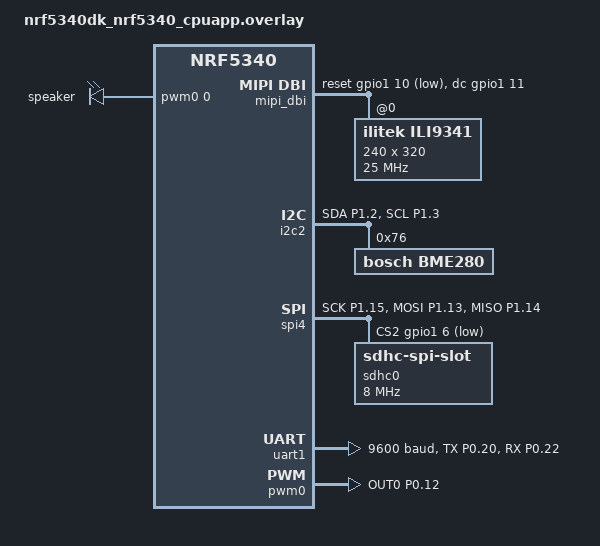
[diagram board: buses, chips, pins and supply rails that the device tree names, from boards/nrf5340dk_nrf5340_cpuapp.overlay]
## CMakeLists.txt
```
#
# Copyright (c) 2024 Nordic Semiconductor
#
# SPDX-License-Identifier: LicenseRef-Nordic-5-Clause
#

cmake_minimum_required(VERSION 3.20.0)
find_package(Zephyr REQUIRED HINTS $ENV{ZEPHYR_BASE})
project(INDOOR)

# Add SRAMLink library
add_subdirectory(lib/sramlink)

target_sources(app PRIVATE src/main.c src/font.c src/font_16x16.c src/prayerTime.c src/world_cities.c src/sd_card.c)

# Conditional display driver - SPI TFT for nrf5340dk and nrf52840dk, parallel for nrf52dk
if(BOARD MATCHES "nrf5340" OR BOARD MATCHES "nrf52840")
    target_sources(app PRIVATE src/ili9341_tft.c)
    message(STATUS "Using ili9341_tft.c (SPI TFT with HMI) for ${BOARD}")
else()
    target_sources(app PRIVATE src/ili9341_parallel.c)
    message(STATUS "Using ili9341_parallel.c (parallel interface) for ${BOARD}")
endif()

# Conditional GPS module selection (default to NEO-7M)
# To use NEO-6M: add -DUSE_NEO6M_GPS=1 to build command
# To use NEO-7M: add -DUSE_NEO7M_GPS=1 to build command (or use default)
if(DEFINED USE_NEO6M_GPS)
    target_sources(app PRIVATE src/gps_neo6m.c)
    target_compile_definitions(app PRIVATE USE_NEO6M_GPS)
    message(STATUS "Using NEO-6M GPS module")
elseif(DEFINED USE_NEO7M_GPS)
    target_sources(app PRIVATE src/gps_neo7m.c)
    target_compile_definitions(app PRIVATE USE_NEO7M_GPS)
    message(STATUS "Using NEO-7M GPS module")
else()
    # Default to NEO-7M
    target_sources(app PRIVATE src/gps_neo7m.c)
    target_compile_definitions(app PRIVATE USE_NEO7M_GPS)
    message(STATUS "Using NEO-7M GPS module (default)")
endif()

# Conditional speaker support - include speaker.c (will compile conditionally based on PWM availability)
if(CONFIG_PWM)
    target_sources(app PRIVATE src/speaker.c)
    message(STATUS "Speaker support enabled (PWM available)")
else()
    message(STATUS "Speaker support disabled (no PWM)")
endif()

# BME280 sensor support - include bme280_sensor.c if sensor is enabled
if(CONFIG_BME280)
    target_sources(app PRIVATE src/bme280_sensor.c)
    message(STATUS "BME280 sensor support enabled")
else()
    message(STATUS "BME280 sensor support disabled")
endif()

# PmodALS ambient light sensor support - only for nRF5340 (uses SPI4)
if(BOARD MATCHES "nrf5340")
    target_sources(app PRIVATE src/pmodals_sensor.c)
    message(STATUS "PmodALS ambient light sensor support enabled")
else()
    message(STATUS "PmodALS ambient light sensor disabled (not supported on ${BOARD})")
endif()

# FT6206 touch screen support - only for nRF5340 (uses I2C0)
if(BOARD MATCHES "nrf5340")
    target_sources(app PRIVATE src/ft6206_touch.c)
    target_compile_definitions(app PRIVATE CONFIG_FT6206_TOUCH)
    message(STATUS "FT6206 touch screen support enabled (I2C0)")
else()
    message(STATUS "FT6206 touch screen disabled (not supported on ${BOARD})")
endif()

# SRAMLink protocol support
if(CONFIG_SRAMLINK)
    target_sources(app PRIVATE src/sramlink/sramlink_app.c)
    target_include_directories(app PRIVATE
        ${CMAKE_CURRENT_SOURCE_DIR}/lib/sramlink
        ${CMAKE_CURRENT_SOURCE_DIR}/lib/sramlink/core
        ${CMAKE_CURRENT_SOURCE_DIR}/lib/sramlink/drivers
        ${CMAKE_CURRENT_SOURCE_DIR}/lib/sramlink/messages
        ${CMAKE_CURRENT_SOURCE_DIR}/lib/sramlink/util
    )
    target_link_libraries(app PRIVATE sramlink)
    message(STATUS "SRAMLink protocol support enabled")
endif()
```

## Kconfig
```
#
# INDOOR Project Kconfig
#

# Source Zephyr Kconfig
source "Kconfig.zephyr"

# Source SRAMLink library Kconfig
rsource "lib/sramlink/Kconfig"
```

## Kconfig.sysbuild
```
source "${ZEPHYR_BASE}/share/sysbuild/Kconfig"

config NRF_DEFAULT_IPC_RADIO
    default y

config NETCORE_IPC_RADIO_BT_HCI_IPC
    default y
```

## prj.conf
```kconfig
CONFIG_GPIO=y
CONFIG_SPI=y
CONFIG_DISPLAY=y
CONFIG_DISPLAY_INIT_PRIORITY=90
CONFIG_ILI9341=y
CONFIG_SERIAL=y
CONFIG_UART_INTERRUPT_DRIVEN=y
CONFIG_UART_ASYNC_API=y
CONFIG_PRINTK=y
CONFIG_PWM=y

# Console configuration - Using RTT instead of UART
CONFIG_CONSOLE=y
CONFIG_UART_CONSOLE=n
CONFIG_RTT_CONSOLE=y
CONFIG_USE_SEGGER_RTT=y
CONFIG_LOG_BACKEND_RTT=y

CONFIG_I2C=y

# Use NFC pins (P0.02, P0.03) as GPIOs for FT6206 touch I2C0
CONFIG_NFCT_PINS_AS_GPIOS=y

# BME280 sensor configuration
CONFIG_SENSOR=y
CONFIG_BME280=y

# PmodALS ambient light sensor configuration
# Uses SPI interface (shared with display on SPI4)
# Note: PmodALS driver is custom implementation, not using Zephyr sensor API

# Logging and support configs
CONFIG_LOG=y
CONFIG_CBPRINTF_FP_SUPPORT=y
CONFIG_RESET_ON_FATAL_ERROR=n

# Heap memory management
CONFIG_HEAP_MEM_POOL_SIZE=32768

# Stack size configuration
CONFIG_MAIN_STACK_SIZE=4096
CONFIG_SYSTEM_WORKQUEUE_STACK_SIZE=2048

# Events (for athan thread signaling)
CONFIG_EVENTS=y

# SD Card and File System Support
CONFIG_FILE_SYSTEM=y
CONFIG_FAT_FILESYSTEM_ELM=y
CONFIG_FS_FATFS_LFN=y
CONFIG_FS_FATFS_MAX_LFN=255

# SD Card / Disk Access
CONFIG_DISK_ACCESS=y
CONFIG_DISK_DRIVER_SDMMC=y
CONFIG_SDMMC_STACK=y
CONFIG_MMC_STACK=y

# SD Card Tuning
CONFIG_SD_INIT_TIMEOUT=5000
CONFIG_SD_RETRY_COUNT=30
CONFIG_SD_OCR_RETRY_COUNT=3000
CONFIG_SD_CMD_TIMEOUT=1000
CONFIG_SD_CMD_RETRIES=10
CONFIG_SD_DATA_RETRIES=10

# SD Card Debug Logging (optional - can be disabled later)
CONFIG_SD_LOG_LEVEL_INF=y
CONFIG_SDHC_LOG_LEVEL_INF=y

# ============================================================
# SRAMLink Protocol Support (optional)
# Uncomment the following to enable SRAMLink wireless protocol
# Or use: west build -- -DOVERLAY_CONFIG=prj_sramlink.conf
# ============================================================
# CONFIG_IEEE802154=y
# CONFIG_IEEE802154_NRF5=y
# CONFIG_SRAMLINK=y
# CONFIG_SRAMLINK_RADIO_CHANNEL=15
# CONFIG_NVS=y
# CONFIG_FLASH=y
# CONFIG_FLASH_MAP=y
# CONFIG_MBEDTLS=y
# CONFIG_MBEDTLS_BUILTIN=y
# CONFIG_MBEDTLS_CIPHER_AES_ENABLED=y
```

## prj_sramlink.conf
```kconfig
#
# SRAMLink Protocol Configuration Overlay
#
# Use this with: west build -b <board> -- -DOVERLAY_CONFIG=prj_sramlink.conf
#

# nRF 802.15.4 Radio Driver (standalone, no networking stack)
CONFIG_NRF_802154_RADIO_DRIVER=y
CONFIG_NRF_802154_SL_OPENSOURCE=y
CONFIG_MPSL=n

# SRAMLink Protocol
CONFIG_SRAMLINK=y
CONFIG_SRAMLINK_LOG_LEVEL=3
CONFIG_SRAMLINK_RADIO_CHANNEL=15
CONFIG_SRAMLINK_TX_POWER=4

# Crypto support (for message encryption) - using Nordic Security
CONFIG_ENTROPY_GENERATOR=y
CONFIG_NRF_SECURITY=y
CONFIG_MBEDTLS=y
CONFIG_MBEDTLS_ENABLE_HEAP=y
CONFIG_MBEDTLS_HEAP_SIZE=8192
CONFIG_PSA_WANT_ALG_CBC_NO_PADDING=y
CONFIG_PSA_WANT_ALG_ECB_NO_PADDING=y
CONFIG_PSA_WANT_KEY_TYPE_AES=y

# Enable legacy mbedTLS AES API
CONFIG_MBEDTLS_AES_C=y
CONFIG_MBEDTLS_CIPHER_AES_ENABLED=y
CONFIG_MBEDTLS_LEGACY_CRYPTO_C=y

# NVS for pairing persistence
CONFIG_NVS=y
CONFIG_FLASH=y
CONFIG_FLASH_PAGE_LAYOUT=y
CONFIG_FLASH_MAP=y
CONFIG_MPU_ALLOW_FLASH_WRITE=y

# Increase stack size for crypto operations
CONFIG_MAIN_STACK_SIZE=8192
```

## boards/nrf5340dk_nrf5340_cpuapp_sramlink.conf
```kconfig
#
# SRAMLink Configuration for nRF5340-DK (App Core)
#
# Uses serialized 802.15.4 driver - network core runs ipc_radio
#

# Enable UART console (override RTT from main prj.conf)
CONFIG_UART_CONSOLE=y
CONFIG_RTT_CONSOLE=n
CONFIG_LOG_BACKEND_RTT=n
CONFIG_LOG_BACKEND_UART=y

# SRAMLink Protocol
CONFIG_SRAMLINK=y
CONFIG_SRAMLINK_LOG_LEVEL=3
CONFIG_SRAMLINK_RADIO_CHANNEL=15
CONFIG_SRAMLINK_TX_POWER=4

# Serialized 802.15.4 driver (communicates with network core)
CONFIG_NRF_802154_SER_HOST=y

# Crypto support
CONFIG_ENTROPY_GENERATOR=y
CONFIG_NRF_SECURITY=y
CONFIG_MBEDTLS=y
CONFIG_MBEDTLS_ENABLE_HEAP=y
CONFIG_MBEDTLS_HEAP_SIZE=8192
CONFIG_PSA_WANT_ALG_CBC_NO_PADDING=y
CONFIG_PSA_WANT_ALG_ECB_NO_PADDING=y
CONFIG_PSA_WANT_KEY_TYPE_AES=y
CONFIG_MBEDTLS_AES_C=y
CONFIG_MBEDTLS_CIPHER_AES_ENABLED=y
CONFIG_MBEDTLS_LEGACY_CRYPTO_C=y

# NVS for pairing persistence
CONFIG_NVS=y
CONFIG_FLASH=y
CONFIG_FLASH_PAGE_LAYOUT=y
CONFIG_FLASH_MAP=y
CONFIG_MPU_ALLOW_FLASH_WRITE=y

# Increase stack size
CONFIG_MAIN_STACK_SIZE=8192
```

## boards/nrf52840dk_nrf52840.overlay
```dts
// nRF52840 DK to Adafruit 1947 LCD Overlay with GPS
&i2c0 {
    status = "okay";
    pinctrl-0 = <&i2c0_default>;
    pinctrl-1 = <&i2c0_sleep>;
    pinctrl-names = "default", "sleep";

    bme280: bme280@76 {
        compatible = "bosch,bme280";
        reg = <0x76>;
        label = "BME280";
    };
};

&spi0 { status = "disabled"; };
&i2c1 { status = "disabled"; };

&spi1 {
    status = "okay";
    pinctrl-0 = <&spi1_default>;
    pinctrl-1 = <&spi1_sleep>;
    pinctrl-names = "default", "sleep";
    cs-gpios = <&gpio1 12 GPIO_ACTIVE_LOW>,  // P1.12 as TFT CS
               <&gpio1 7 GPIO_ACTIVE_LOW>;   // P1.07 as ALS CS
};

/* Add pinctrl node for spi1 */
&pinctrl {
    i2c0_default: i2c0_default {
        group1 {
            psels = <NRF_PSEL(TWIM_SCL, 0, 28)>,
                    <NRF_PSEL(TWIM_SDA, 0, 29)>;
        };
    };

    i2c0_sleep: i2c0_sleep {
        group1 {
            psels = <NRF_PSEL(TWIM_SCL, 0, 28)>,
                    <NRF_PSEL(TWIM_SDA, 0, 29)>;
            low-power-enable;
        };
    };

    spi1_default: spi1_default {
        group1 {
            psels = <NRF_PSEL(SPIM_SCK, 1, 15)>,   // P1.15 SCLK
                    <NRF_PSEL(SPIM_MOSI, 1, 13)>,  // P1.13 MOSI
                    <NRF_PSEL(SPIM_MISO, 1, 14)>;  // P1.14 MISO
         };
    };

    spi1_sleep: spi1_sleep {
        group1 {
            psels = <NRF_PSEL(SPIM_SCK, 1, 15)>,
                    <NRF_PSEL(SPIM_MOSI, 1, 13)>,
                    <NRF_PSEL(SPIM_MISO, 1, 14)>;
            low-power-enable;
        };
    };

    pwm0_default: pwm0_default {
        group1 {
            psels = <NRF_PSEL(PWM_OUT0, 0, 12)>;  // P0.12 Speaker PWM
        };
    };

    pwm0_sleep: pwm0_sleep {
        group1 {
            psels = <NRF_PSEL(PWM_OUT0, 0, 12)>;
            low-power-enable;
        };
    };
};

/ {
    aliases {
        gps-uart = &uart1;
    };

    chosen {
        zephyr,console = &uart0;
        zephyr,shell-uart = &uart0;
        zephyr,uart-mcumgr = &uart0;
        zephyr,display = &ili9341;
    };

    backlight: backlight {
        compatible = "gpio-leds";
        backlight_gpio: backlight_gpio {
            gpios = <&gpio0 3 GPIO_ACTIVE_LOW>;
            label = "Display Backlight";
        };
    };

    pwmleds {
        compatible = "pwm-leds";
        speaker: speaker_pwm_led {
            pwms = <&pwm0 0 PWM_HZ(1000) PWM_POLARITY_NORMAL>;
        };
    };

    mipi_dbi {
        compatible = "zephyr,mipi-dbi-spi";
        spi-dev = <&spi1>;
        dc-gpios = <&gpio1 11 GPIO_ACTIVE_HIGH>;
        status = "okay";
        #address-cells = <1>;
        #size-cells = <0>;

        ili9341: ili9341@0 {
            compatible = "ilitek,ili9341";
            reg = <0>;
            mipi-max-frequency = <25000000>;
            width = <240>;
            height = <320>;
            rotation = <90>;
            gamset = [01];
        };
    };

};

&uart0 {
    status = "okay";
    current-speed = <115200>;
};

&uart1 {
    status = "okay";
    current-speed = <9600>;
    pinctrl-0 = <&uart1_default>;
    pinctrl-1 = <&uart1_sleep>;
    pinctrl-names = "default", "sleep";
};

// PWM0 for Speaker (P0.12)
&pwm0 {
    status = "okay";
    pinctrl-0 = <&pwm0_default>;
    pinctrl-1 = <&pwm0_sleep>;
    pinctrl-names = "default", "sleep";
};

&pinctrl {
    uart1_default: uart1_default {
        group1 {
            psels = <NRF_PSEL(UART_TX, 1, 1)>,
                    <NRF_PSEL(UART_RX, 1, 2)>;
        };
    };

    uart1_sleep: uart1_sleep {
        group1 {
            psels = <NRF_PSEL(UART_TX, 1, 1)>,
                    <NRF_PSEL(UART_RX, 1, 2)>;
            low-power-enable;
        };
    };
};

/// Pin Mapping Summary (Essential connections only):
// P1.15 - SCK      -  (D13) - Shared SPI1 CLK
// P1.13 - MOSI     -  (D11) - Shared SPI1 MOSI
// P1.14 - MISO     -  (D12) - Shared SPI1 MISO
// P1.12 - TFT CS   -  (D10) - ILI9341 Display CS
// P1.11 - DC       -  (D09) - ILI9341 Display DC
// P1.10 - RESET    -  (D08) - ILI9341 Display Reset (manual in code)
// P1.07 - ALS CS   -  PmodALS chip select
// P1.01 - GPS TX   -  UART1 TX (connect to GPS RX)
// P1.02 - GPS RX   -  UART1 RX (connect to GPS TX)
// P0.28 - I2C SCL  -  I2C0 SCL (BME280 & FT6206)
// P0.29 - I2C SDA  -  I2C0 SDA (BME280 & FT6206)
// P0.04 - Touch IRQ - FT6206 interrupt (Adafruit 1947 touch)
// P0.03 - Backlight - Display backlight control
// P0.12 - Speaker   - PWM speaker output
```

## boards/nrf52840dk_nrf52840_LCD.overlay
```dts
/ {
	lcd_parallel {
		compatible = "gpio-leds";

		/* 8-bit Data Bus */
		lcd_d0: lcd_d0 {
			gpios = <&gpio1 10 GPIO_ACTIVE_HIGH>;
		};
		lcd_d1: lcd_d1 {
			gpios = <&gpio1 11 GPIO_ACTIVE_HIGH>;
		};
		lcd_d2: lcd_d2 {
			gpios = <&gpio1 3 GPIO_ACTIVE_HIGH>;
		};
		lcd_d3: lcd_d3 {
			gpios = <&gpio1 4 GPIO_ACTIVE_HIGH>;
		};
		lcd_d4: lcd_d4 {
			gpios = <&gpio1 5 GPIO_ACTIVE_HIGH>;
		};
		lcd_d5: lcd_d5 {
			gpios = <&gpio1 6 GPIO_ACTIVE_HIGH>;
		};
		lcd_d6: lcd_d6 {
			gpios = <&gpio1 7 GPIO_ACTIVE_HIGH>;
		};
		lcd_d7: lcd_d7 {
			gpios = <&gpio1 8 GPIO_ACTIVE_HIGH>;
		};

		/* Control Signals */
		lcd_rst: lcd_rst {
			gpios = <&gpio0 30 GPIO_ACTIVE_HIGH>;
		};
		lcd_cs: lcd_cs {
			gpios = <&gpio0 29 GPIO_ACTIVE_HIGH>;
		};
		lcd_rs: lcd_rs {
			gpios = <&gpio0 28 GPIO_ACTIVE_HIGH>;
		};
		lcd_wr: lcd_wr {
			gpios = <&gpio0 4 GPIO_ACTIVE_HIGH>;
		};
		lcd_rd: lcd_rd {
			gpios = <&gpio0 3 GPIO_ACTIVE_HIGH>;
		};
	};
};

/* UART0 - Console/Debug output via USB
 * This is the default console UART on nRF5340-DK
 * Connected to J-Link debugger for USB-to-Serial
 */
&uart0 {
	status = "okay";
	current-speed = <115200>;
};

/* GPS UART Configuration
 * UART1 is used for GPS communication (NEO-6M)
 *
 * GPS NEO-6M Connection:
 *   GPS TX → nRF5340-DK P1.02 (UART1 RX)
 *   GPS RX → nRF5340-DK P1.01 (UART1 TX)
 *   GPS VCC → 3.3V or 5V (check your GPS module)
 *   GPS GND → GND
 */
&uart1 {
	compatible = "nordic,nrf-uarte";
	status = "okay";
	current-speed = <9600>;
	pinctrl-0 = <&uart1_gps>;
	pinctrl-1 = <&uart1_gps_sleep>;
	pinctrl-names = "default", "sleep";
};

&pinctrl {
	uart1_gps: uart1_gps {
		group1 {
			psels = <NRF_PSEL(UART_TX, 1, 01)>,
			        <NRF_PSEL(UART_RX, 1, 02)>;
		};
	};

	uart1_gps_sleep: uart1_gps_sleep {
		group1 {
			psels = <NRF_PSEL(UART_TX, 1, 01)>,
			        <NRF_PSEL(UART_RX, 1, 02)>;
			low-power-enable;
		};
	};
};
```

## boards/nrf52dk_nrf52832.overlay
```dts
/ {
	/* Speaker PWM Configuration */
	speaker {
		compatible = "pwm-leds";
		speaker_pwm: speaker_pwm {
			pwms = <&pwm0 0 PWM_MSEC(20) PWM_POLARITY_NORMAL>;
			label = "Speaker PWM";
		};
	};

	/* SD Card Chip Select GPIO */
	sd_card_cs {
		compatible = "gpio-leds";
		sd_cs: sd_cs {
			gpios = <&gpio0 22 GPIO_ACTIVE_LOW>;
			label = "SD Card CS";
		};
	};

	lcd_pins {
		compatible = "gpio-leds";

		lcd_d0: lcd_d0 {
			gpios = <&gpio0 19 GPIO_ACTIVE_HIGH>;
			label = "LCD D0";
		};
		lcd_d1: lcd_d1 {
			gpios = <&gpio0 20 GPIO_ACTIVE_HIGH>;
			label = "LCD D1";
		};
		lcd_d2: lcd_d2 {
			gpios = <&gpio0 13 GPIO_ACTIVE_HIGH>;
			label = "LCD D2";
		};
		lcd_d3: lcd_d3 {
			gpios = <&gpio0 14 GPIO_ACTIVE_HIGH>;
			label = "LCD D3";
		};
		lcd_d4: lcd_d4 {
			gpios = <&gpio0 15 GPIO_ACTIVE_HIGH>;
			label = "LCD D4";
		};
		lcd_d5: lcd_d5 {
			gpios = <&gpio0 16 GPIO_ACTIVE_HIGH>;
			label = "LCD D5";
		};
		lcd_d6: lcd_d6 {
			gpios = <&gpio0 17 GPIO_ACTIVE_HIGH>;
			label = "LCD D6";
		};
		lcd_d7: lcd_d7 {
			gpios = <&gpio0 18 GPIO_ACTIVE_HIGH>;
			label = "LCD D7";
		};

		lcd_rst: lcd_rst {
			gpios = <&gpio0 30 GPIO_ACTIVE_HIGH>;
			label = "LCD RST";
		};
		lcd_cs: lcd_cs {
			gpios = <&gpio0 29 GPIO_ACTIVE_HIGH>;
			label = "LCD CS";
		};
		lcd_rs: lcd_rs {
			gpios = <&gpio0 28 GPIO_ACTIVE_HIGH>;
			label = "LCD RS/DC";
		};
		lcd_wr: lcd_wr {
			gpios = <&gpio0 4 GPIO_ACTIVE_HIGH>;
			label = "LCD WR";
		};
		lcd_rd: lcd_rd {
			gpios = <&gpio0 3 GPIO_ACTIVE_HIGH>;
			label = "LCD RD";
		};
	};
};

/* GPS UART Configuration
 * UART0 is used for GPS communication
 * Console/debug uses RTT (SEGGER Real-Time Transfer)
 *
 * Using nRF52-DK default UART pins (normally used for USB UART):
 *   GPS TX → nRF52-DK P0.08 (UART RX)
 *   GPS RX → nRF52-DK P0.06 (UART TX)
 *   GPS VCC → VDD (3.3V) or 5V (check your GPS module)
 *   GPS GND → GND
 *
 * Note: P0.06 and P0.08 are the standard UART pins on nRF52-DK
 */
&uart0 {
	compatible = "nordic,nrf-uarte";
	status = "okay";
	current-speed = <9600>;  /* Back to 9600 baud */
	pinctrl-0 = <&uart0_gps>;
	pinctrl-1 = <&uart0_gps_sleep>;
	pinctrl-names = "default", "sleep";
};

&pinctrl {
	uart0_gps: uart0_gps {
		group1 {
			psels = <NRF_PSEL(UART_TX, 0, 6)>,
			        <NRF_PSEL(UART_RX, 0, 8)>;
		};
	};

	uart0_gps_sleep: uart0_gps_sleep {
		group1 {
			psels = <NRF_PSEL(UART_TX, 0, 6)>,
			        <NRF_PSEL(UART_RX, 0, 8)>;
			low-power-enable;
		};
	};

	/* SPI for SD Card
	 * P0.25 - SCK  (SD_SCK)
	 * P0.23 - MOSI (SD_DI)
	 * P0.24 - MISO (SD_SO)
	 * P0.22 - CS   (SD_SS) - controlled manually as GPIO
	 */
	spi1_sd: spi1_sd {
		group1 {
			psels = <NRF_PSEL(SPIM_SCK, 0, 25)>,
			        <NRF_PSEL(SPIM_MOSI, 0, 23)>,
			        <NRF_PSEL(SPIM_MISO, 0, 24)>;
		};
	};

	spi1_sd_sleep: spi1_sd_sleep {
		group1 {
			psels = <NRF_PSEL(SPIM_SCK, 0, 25)>,
			        <NRF_PSEL(SPIM_MOSI, 0, 23)>,
			        <NRF_PSEL(SPIM_MISO, 0, 24)>;
			low-power-enable;
		};
	};

	/* PWM0 for speaker on P0.01 */
	pwm0_speaker: pwm0_speaker {
		group1 {
			psels = <NRF_PSEL(PWM_OUT0, 0, 1)>;
			nordic,invert;
		};
	};

	pwm0_speaker_sleep: pwm0_speaker_sleep {
		group1 {
			psels = <NRF_PSEL(PWM_OUT0, 0, 1)>;
			low-power-enable;
		};
	};
};

/* Enable PWM0 for Speaker */
&pwm0 {
	status = "okay";
	pinctrl-0 = <&pwm0_speaker>;
	pinctrl-1 = <&pwm0_speaker_sleep>;
	pinctrl-names = "default", "sleep";
};

/* Enable SPI1 for SD Card */
&spi1 {
	compatible = "nordic,nrf-spi";
	status = "okay";
	cs-gpios = <&gpio0 22 GPIO_ACTIVE_LOW>;
	pinctrl-0 = <&spi1_sd>;
	pinctrl-1 = <&spi1_sd_sleep>;
	pinctrl-names = "default", "sleep";

	sdhc0: sdhc@0 {
		compatible = "zephyr,sdhc-spi-slot";
		reg = <0>;
		status = "okay";
		spi-max-frequency = <8000000>;
		mmc {
			compatible = "zephyr,sdmmc-disk";
			status = "okay";
		};
	};
};
```

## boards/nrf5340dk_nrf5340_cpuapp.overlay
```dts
// nRF5340 DK - GPS Display Application Overlay
// Target: nRF5340 Application Core (nrf5340dk/nrf5340/cpuapp)
// Peripherals: GPS UART1 + ILI9341 TFT Display

// Disable unused peripherals
&spi0 { status = "disabled"; };
&i2c0 { status = "disabled"; };
&i2c1 { status = "disabled"; };

// Enable I2C2 for BME280 sensor
&i2c2 {
    status = "okay";
    pinctrl-0 = <&i2c2_default>;
    pinctrl-1 = <&i2c2_sleep>;
    pinctrl-names = "default", "sleep";

    bme280: bme280@76 {
        compatible = "bosch,bme280";
        reg = <0x76>;
        label = "BME280";
    };
};

// SPI4 for TFT Display, PmodALS, and SD Card (shared bus)
&spi4 {
    status = "okay";
    pinctrl-0 = <&spi4_default>;
    pinctrl-1 = <&spi4_sleep>;
    pinctrl-names = "default", "sleep";
    cs-gpios = <&gpio1 12 GPIO_ACTIVE_LOW>,  // P1.12 as TFT CS (device 0)
               <&gpio1 7 GPIO_ACTIVE_LOW>,   // P1.07 as ALS CS (device 1)
               <&gpio1 6 GPIO_ACTIVE_LOW>;   // P1.06 as SD Card CS (device 2)

    sdhc0: sdhc@2 {
        compatible = "zephyr,sdhc-spi-slot";
        reg = <2>;
        spi-max-frequency = <8000000>;
        status = "okay";
        mmc {
            compatible = "zephyr,sdmmc-disk";
            status = "okay";
        };
    };
};

/* Pinctrl configurations */
&pinctrl {
    i2c2_default: i2c2_default {
        group1 {
            psels = <NRF_PSEL(TWIM_SDA, 1, 2)>,    // P1.02 I2C SDA
                    <NRF_PSEL(TWIM_SCL, 1, 3)>;    // P1.03 I2C SCL
        };
    };

    i2c2_sleep: i2c2_sleep {
        group1 {
            psels = <NRF_PSEL(TWIM_SDA, 1, 2)>,
                    <NRF_PSEL(TWIM_SCL, 1, 3)>;
            low-power-enable;
        };
    };

    spi4_default: spi4_default {
        group1 {
            psels = <NRF_PSEL(SPIM_SCK, 1, 15)>,   // P1.15 SCLK
                    <NRF_PSEL(SPIM_MOSI, 1, 13)>,  // P1.13 MOSI
                    <NRF_PSEL(SPIM_MISO, 1, 14)>;  // P1.14 MISO
         };
    };

    spi4_sleep: spi4_sleep {
        group1 {
            psels = <NRF_PSEL(SPIM_SCK, 1, 15)>,
                    <NRF_PSEL(SPIM_MOSI, 1, 13)>,
                    <NRF_PSEL(SPIM_MISO, 1, 14)>;
            low-power-enable;
        };
    };

    uart1_gps: uart1_gps {
        group1 {
            psels = <NRF_PSEL(UART_TX, 0, 20)>,  // P0.20 UART1 TX (to GPS RX)
                    <NRF_PSEL(UART_RX, 0, 22)>;  // P0.22 UART1 RX (from GPS TX)
        };
    };

    uart1_gps_sleep: uart1_gps_sleep {
        group1 {
            psels = <NRF_PSEL(UART_TX, 0, 20)>,
                    <NRF_PSEL(UART_RX, 0, 22)>;
            low-power-enable;
        };
    };

    pwm0_default: pwm0_default {
        group1 {
            psels = <NRF_PSEL(PWM_OUT0, 0, 12)>;  // P0.12 Speaker PWM
        };
    };

    pwm0_sleep: pwm0_sleep {
        group1 {
            psels = <NRF_PSEL(PWM_OUT0, 0, 12)>;
            low-power-enable;
        };
    };
};

/ {
    aliases {
        gps-uart = &uart1;
    };

    chosen {
        zephyr,display = &ili9341;
    };

    pwmleds {
        compatible = "pwm-leds";
        speaker: speaker_pwm_led {
            pwms = <&pwm0 0 PWM_HZ(1000) PWM_POLARITY_NORMAL>;
        };
    };

    mipi_dbi {
        compatible = "zephyr,mipi-dbi-spi";
        spi-dev = <&spi4>;
        dc-gpios = <&gpio1 11 GPIO_ACTIVE_HIGH>;    // P1.11 DC
        reset-gpios = <&gpio1 10 GPIO_ACTIVE_LOW>;  // P1.10 RESET
        status = "okay";
        #address-cells = <1>;
        #size-cells = <0>;

        ili9341: ili9341@0 {
            compatible = "ilitek,ili9341";
            reg = <0>;
            mipi-max-frequency = <25000000>;
            width = <240>;
            height = <320>;
            rotation = <90>;  // Landscape mode: 320x240
            gamset = [01];
        };
    };
};

// UART1 for GPS (9600 baud)
&uart1 {
    compatible = "nordic,nrf-uarte";
    status = "okay";
    current-speed = <9600>;
    pinctrl-0 = <&uart1_gps>;
    pinctrl-1 = <&uart1_gps_sleep>;
    pinctrl-names = "default", "sleep";
};

// PWM0 for Speaker (P0.12)
&pwm0 {
    status = "okay";
    pinctrl-0 = <&pwm0_default>;
    pinctrl-1 = <&pwm0_sleep>;
    pinctrl-names = "default", "sleep";
};

/// Pin Mapping Summary:
// GPS UART1:
//   P0.20 - UART TX  (connect to GPS RX)
//   P0.22 - UART RX  (connect from GPS TX)
//
// TFT Display, PmodALS, SD Card, and Touch Screen (Shared SPI4 bus):
//   P1.15 - SCK      (Shared SPI4 CLK)
//   P1.13 - MOSI     (Shared SPI4 MOSI)
//   P1.14 - MISO     (Shared SPI4 MISO)
//   P1.12 - TFT CS   (ILI9341 Display CS, SPI device 0)
//   P1.11 - DC       (ILI9341 Display DC)
//   P1.10 - RESET    (ILI9341 Display Reset)
//   P1.07 - ALS CS   (PmodALS chip select, SPI device 1)
//   P1.06 - SD CS    (SD Card chip select, SPI device 2)
//   P1.08 - TOUCH CS (STMPE610 Touch controller CS, SPI device 3)
//   P1.00 - TOUCH IRQ (Touch interrupt, optional)
//
// BME280 Sensor and FT6206 Touch (I2C2):
//   P1.02 - I2C SDA  (BME280 & FT6206 data line)
//   P1.03 - I2C SCL  (BME280 & FT6206 clock line)
//   P1.00 - Touch IRQ (FT6206 interrupt)
//
// Speaker (PWM0):
//   P0.12 - PWM OUT  (Speaker/Buzzer signal)
```

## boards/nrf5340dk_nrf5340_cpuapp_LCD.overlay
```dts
/ {
	lcd_parallel {
		compatible = "gpio-leds";

		/* 8-bit Data Bus */
		lcd_d0: lcd_d0 {
			gpios = <&gpio1 10 GPIO_ACTIVE_HIGH>;
		};
		lcd_d1: lcd_d1 {
			gpios = <&gpio1 11 GPIO_ACTIVE_HIGH>;
		};
		lcd_d2: lcd_d2 {
			gpios = <&gpio1 4 GPIO_ACTIVE_HIGH>;
		};
		lcd_d3: lcd_d3 {
			gpios = <&gpio1 5 GPIO_ACTIVE_HIGH>;
		};
		lcd_d4: lcd_d4 {
			gpios = <&gpio1 6 GPIO_ACTIVE_HIGH>;
		};
		lcd_d5: lcd_d5 {
			gpios = <&gpio1 7 GPIO_ACTIVE_HIGH>;
		};
		lcd_d6: lcd_d6 {
			gpios = <&gpio1 8 GPIO_ACTIVE_HIGH>;
		};
		lcd_d7: lcd_d7 {
			gpios = <&gpio1 9 GPIO_ACTIVE_HIGH>;
		};

		/* Control Signals */
		lcd_rst: lcd_rst {
			gpios = <&gpio0 25 GPIO_ACTIVE_HIGH>;
		};
		lcd_cs: lcd_cs {
			gpios = <&gpio0 7 GPIO_ACTIVE_HIGH>;
		};
		lcd_rs: lcd_rs {
			gpios = <&gpio0 6 GPIO_ACTIVE_HIGH>;
		};
		lcd_wr: lcd_wr {
			gpios = <&gpio0 5 GPIO_ACTIVE_HIGH>;
		};
		lcd_rd: lcd_rd {
			gpios = <&gpio0 4 GPIO_ACTIVE_HIGH>;
		};
	};
};

/* UART0 - Console/Debug output via USB
 * This is the default console UART on nRF5340-DK
 * Connected to J-Link debugger for USB-to-Serial
 */
&uart0 {
	status = "okay";
	current-speed = <115200>;
};

/* GPS UART Configuration
 * UART1 is used for GPS communication (NEO-6M)
 *
 * GPS NEO-6M Connection:
 *   GPS TX → nRF5340-DK P0.22 (UART1 RX)
 *   GPS RX → nRF5340-DK P0.20 (UART1 TX)
 *   GPS VCC → 3.3V or 5V (check your GPS module)
 *   GPS GND → GND
 */
&uart1 {
	compatible = "nordic,nrf-uarte";
	status = "okay";
	current-speed = <9600>;
	pinctrl-0 = <&uart1_gps>;
	pinctrl-1 = <&uart1_gps_sleep>;
	pinctrl-names = "default", "sleep";
};

&pinctrl {
	uart1_gps: uart1_gps {
		group1 {
			psels = <NRF_PSEL(UART_TX, 0, 20)>,
			        <NRF_PSEL(UART_RX, 0, 22)>;
		};
	};

	uart1_gps_sleep: uart1_gps_sleep {
		group1 {
			psels = <NRF_PSEL(UART_TX, 0, 20)>,
			        <NRF_PSEL(UART_RX, 0, 22)>;
			low-power-enable;
		};
	};
};
```

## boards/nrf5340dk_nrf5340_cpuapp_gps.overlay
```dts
// nRF5340 DK - GPS Display Application Overlay
// Target: nRF5340 Application Core (nrf5340dk/nrf5340/cpuapp)
// Peripherals: GPS UART1 + ILI9341 TFT Display

// Disable unused peripherals
&spi0 { status = "disabled"; };
&i2c0 { status = "disabled"; };
&i2c1 { status = "disabled"; };
&i2c2 { status = "disabled"; };

// SPI4 for TFT Display
&spi4 {
    status = "okay";
    pinctrl-0 = <&spi4_default>;
    pinctrl-1 = <&spi4_sleep>;
    pinctrl-names = "default", "sleep";
    cs-gpios = <&gpio1 12 GPIO_ACTIVE_LOW>;  // P1.12 as TFT CS
};

/* Pinctrl configurations */
&pinctrl {
    spi4_default: spi4_default {
        group1 {
            psels = <NRF_PSEL(SPIM_SCK, 1, 15)>,   // P1.15 SCLK
                    <NRF_PSEL(SPIM_MOSI, 1, 13)>,  // P1.13 MOSI
                    <NRF_PSEL(SPIM_MISO, 1, 14)>;  // P1.14 MISO
         };
    };

    spi4_sleep: spi4_sleep {
        group1 {
            psels = <NRF_PSEL(SPIM_SCK, 1, 15)>,
                    <NRF_PSEL(SPIM_MOSI, 1, 13)>,
                    <NRF_PSEL(SPIM_MISO, 1, 14)>;
            low-power-enable;
        };
    };

    uart1_gps: uart1_gps {
        group1 {
            psels = <NRF_PSEL(UART_TX, 0, 20)>,  // P0.20 UART1 TX (to GPS RX)
                    <NRF_PSEL(UART_RX, 0, 22)>;  // P0.22 UART1 RX (from GPS TX)
        };
    };

    uart1_gps_sleep: uart1_gps_sleep {
        group1 {
            psels = <NRF_PSEL(UART_TX, 0, 20)>,
                    <NRF_PSEL(UART_RX, 0, 22)>;
            low-power-enable;
        };
    };
};

/ {
    aliases {
        gps-uart = &uart1;
    };

    chosen {
        zephyr,display = &ili9341;
    };

    mipi_dbi {
        compatible = "zephyr,mipi-dbi-spi";
        spi-dev = <&spi4>;
        dc-gpios = <&gpio1 11 GPIO_ACTIVE_HIGH>;    // P1.11 DC
        reset-gpios = <&gpio1 10 GPIO_ACTIVE_LOW>;  // P1.10 RESET
        status = "okay";
        #address-cells = <1>;
        #size-cells = <0>;

        ili9341: ili9341@0 {
            compatible = "ilitek,ili9341";
            reg = <0>;
            mipi-max-frequency = <25000000>;
            width = <240>;
            height = <320>;
            rotation = <90>;  // Landscape mode: 320x240
            gamset = [01];
        };
    };
};

// UART1 for GPS (9600 baud)
&uart1 {
    compatible = "nordic,nrf-uarte";
    status = "okay";
    current-speed = <9600>;
    pinctrl-0 = <&uart1_gps>;
    pinctrl-1 = <&uart1_gps_sleep>;
    pinctrl-names = "default", "sleep";
};

/// Pin Mapping Summary:
// GPS UART1:
//   P0.20 - UART TX  (connect to GPS RX)
//   P0.22 - UART RX  (connect from GPS TX)
//
// TFT Display (SPI4):
//   P1.15 - SCK      (Shared SPI4 CLK)
//   P1.13 - MOSI     (Shared SPI4 MOSI)
//   P1.14 - MISO     (Shared SPI4 MISO)
//   P1.12 - TFT CS   (ILI9341 Display CS)
//   P1.11 - DC       (ILI9341 Display DC)
//   P1.10 - RESET    (ILI9341 Display Reset)
```

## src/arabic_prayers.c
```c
// Auto-generated Arabic prayer time bitmaps
// Generated by generate_arabic_prayers.py

#include <stdint.h>

// مواقيت الصلاة
const uint8_t arabic_مواقيت_الصلاة[] = {
0x00, 0x00, 0x00, 0x00, 0x00, 0x00, 0x41, 0x00, 0x00, 0x00, 0x00, 0x00, 0x00, 0x20, 0x00, 0x00,
0x00, 0x00, 0x00, 0xC0, 0x00, 0x00, 0xC1, 0x00, 0x00, 0x00, 0x00, 0x00, 0x10, 0x20, 0x00, 0x00,
0x02, 0x00, 0x01, 0xC0, 0x00, 0x00, 0x47, 0x00, 0x00, 0x00, 0x00, 0x00, 0x58, 0x60, 0x00, 0x00,
0x3F, 0x0C, 0x01, 0xC0, 0x00, 0x00, 0x47, 0x00, 0x00, 0x00, 0x00, 0x00, 0xF8, 0x60, 0x00, 0x00,
0x7E, 0x0F, 0x01, 0xC0, 0x00, 0x00, 0x41, 0x00, 0x00, 0x01, 0x00, 0x00, 0x40, 0x20, 0x00, 0x00,
0x10, 0x0F, 0xC1, 0xC0, 0x00, 0x00, 0x41, 0x00, 0x00, 0x0F, 0x80, 0x00, 0x00, 0x20, 0x00, 0x00,
0x00, 0x0F, 0xE1, 0xC0, 0x00, 0x00, 0x41, 0x00, 0x00, 0x1F, 0x00, 0x00, 0x00, 0x20, 0x00, 0x00,
0x00, 0x07, 0x71, 0xC0, 0x00, 0x00, 0x41, 0x00, 0x00, 0x08, 0x00, 0x00, 0x20, 0x20, 0x00, 0x00,
0x00, 0x00, 0x31, 0xC0, 0x00, 0x00, 0x41, 0x80, 0x00, 0x00, 0x00, 0x00, 0x70, 0x30, 0x00, 0x00,
0x0C, 0x00, 0x19, 0xC0, 0x00, 0x3C, 0x61, 0x80, 0x00, 0x00, 0x00, 0x00, 0x78, 0x30, 0x00, 0x08,
0x1E, 0x00, 0x0A, 0xC0, 0x00, 0xFE, 0x21, 0x80, 0x00, 0x00, 0x00, 0x00, 0x98, 0x30, 0x00, 0x3C,
0x3F, 0x00, 0x06, 0xE0, 0x01, 0xFE, 0x21, 0x80, 0x08, 0x00, 0x00, 0x00, 0xFC, 0x30, 0x00, 0x4C,
0x21, 0x00, 0x04, 0x21, 0x04, 0x1C, 0x20, 0x80, 0x08, 0x00, 0x01, 0x08, 0x08, 0x10, 0x3C, 0xFE,
0x21, 0x00, 0x0C, 0x33, 0xE8, 0xFE, 0x40, 0x80, 0x08, 0x00, 0x03, 0x1E, 0x38, 0x10, 0x25, 0x3C,
0x3F, 0x00, 0x18, 0x3E, 0xFF, 0xFF, 0xC0, 0x80, 0x0C, 0x00, 0x1F, 0xFF, 0xF0, 0x10, 0x3F, 0x04,
0x3E, 0x00, 0x70, 0x1C, 0x1F, 0x87, 0x80, 0x80, 0x0F, 0xFF, 0xFC, 0xE7, 0xC0, 0x10, 0x3E, 0x00,
0x10, 0x07, 0xE0, 0x00, 0x60, 0x00, 0x00, 0x00, 0x07, 0xFF, 0xE0, 0x00, 0x00, 0x00, 0x04, 0x00,
0x00, 0x00, 0x00, 0x00, 0x60, 0x00, 0x00, 0x00, 0x01, 0xFF, 0x00, 0x06, 0x00, 0x00, 0x0C, 0x00,
0x00, 0x00, 0x00, 0x00, 0x00, 0x00, 0x00, 0x00, 0x00, 0x00, 0x00, 0x3F, 0x00, 0x00, 0x08, 0x00,
0x00, 0x00, 0x00, 0x00, 0x00, 0x00, 0x00, 0x00, 0x00, 0x00, 0x00, 0x7E, 0x00, 0x00, 0x18, 0x00,
0x00, 0x00, 0x00, 0x00, 0x00, 0x00, 0x00, 0x00, 0x00, 0x00, 0x00, 0x30, 0x00, 0x00, 0xF0, 0x00,
0x00, 0x00, 0x00, 0x00, 0x00, 0x00, 0x00, 0x00, 0x00, 0x00, 0x00, 0x00, 0x00, 0x1F, 0xE0, 0x00,
0x00, 0x00, 0x00, 0x00, 0x00, 0x00, 0x00, 0x00, 0x00, 0x00, 0x00, 0x00, 0x00, 0x07, 0x00, 0x00,
0x00, 0x00, 0x00, 0x00, 0x00, 0x00, 0x00, 0x00, 0x00, 0x00, 0x00, 0x00, 0x00, 0x00, 0x00, 0x00,
};
#define ARABIC_مواقيت_الصلاة_WIDTH 128
#define ARABIC_مواقيت_الصلاة_HEIGHT 24

// الفجر
const uint8_t arabic_الفجر[] = {
0x00, 0x00, 0x00, 0x00, 0x00, 0x00, 0x00, 0x00, 0x00, 0x00, 0x00, 0x00, 0x03, 0x80, 0x0E, 0x00,
0x00, 0x00, 0x00, 0x00, 0x00, 0x00, 0x00, 0x00, 0x00, 0x00, 0x00, 0x00, 0x1F, 0x80, 0x0E, 0x00,
0x00, 0x00, 0x00, 0x00, 0x00, 0x00, 0x00, 0x00, 0x00, 0x00, 0x01, 0xF8, 0x03, 0x80, 0x7E, 0x00,
0x00, 0x00, 0x00, 0x00, 0x00, 0x00, 0x00, 0x00, 0x00, 0x00, 0x0F, 0xF8, 0x03, 0x80, 0x7E, 0x00,
0x00, 0x00, 0x00, 0x00, 0x00, 0x00, 0x00, 0x00, 0x00, 0x00, 0x01, 0xC0, 0x03, 0x80, 0x0E, 0x00,
0x00, 0x00, 0x00, 0x00, 0x00, 0x00, 0x00, 0x00, 0x00, 0x00, 0x00, 0x00, 0x03, 0x80, 0x0E, 0x00,
0x00, 0x00, 0x00, 0x00, 0x00, 0x00, 0x00, 0x00, 0x00, 0x00, 0x00, 0x00, 0x03, 0x80, 0x0E, 0x00,
0x00, 0x00, 0x00, 0x00, 0x00, 0x00, 0x00, 0x00, 0x00, 0x00, 0x00, 0x00, 0x03, 0x80, 0x0E, 0x00,
0x00, 0x00, 0x00, 0x00, 0x00, 0x00, 0x00, 0x00, 0x00, 0x00, 0x01, 0xF8, 0x03, 0x80, 0x0F, 0xC0,
0x00, 0x00, 0x00, 0x00, 0x00, 0x00, 0x00, 0x00, 0x00, 0x00, 0x0F, 0xFF, 0x03, 0xF0, 0x0F, 0xC0,
0x00, 0x00, 0x00, 0x00, 0xFF, 0xFE, 0x00, 0x00, 0x00, 0x00, 0x0E, 0x3F, 0x00, 0x70, 0x0F, 0xC0,
0x00, 0x00, 0x00, 0x07, 0xFF, 0xFF, 0xFF, 0xC0, 0x03, 0x80, 0x70, 0x07, 0x00, 0x70, 0x0F, 0xC0,
0x00, 0x00, 0x01, 0xC0, 0x00, 0x7F, 0xFF, 0xFF, 0xFC, 0x01, 0xFF, 0xF8, 0x00, 0x70, 0x01, 0xC0,
0x00, 0x00, 0x01, 0xC0, 0xFF, 0xFF, 0x80, 0x07, 0x00, 0x01, 0xFF, 0xF8, 0x03, 0x80, 0x01, 0xC0,
0x00, 0x00, 0x0F, 0xFF, 0xFF, 0x80, 0x00, 0x3F, 0xFF, 0xFF, 0xFF, 0xFF, 0xFF, 0x80, 0x01, 0xC0,
0x00, 0x00, 0x01, 0xFF, 0xE0, 0x00, 0x00, 0x07, 0xFF, 0xFE, 0x00, 0x3F, 0xFC, 0x00, 0x01, 0xC0,
0x00, 0x00, 0x01, 0xC0, 0x00, 0x00, 0x00, 0x00, 0x00, 0x00, 0x00, 0x00, 0x00, 0x00, 0x00, 0x00,
0x00, 0x00, 0x01, 0xC0, 0x00, 0x01, 0xF0, 0x00, 0x00, 0x00, 0x00, 0x00, 0x00, 0x00, 0x00, 0x00,
0x00, 0x00, 0x01, 0xC0, 0x00, 0x0F, 0xFE, 0x00, 0x00, 0x00, 0x00, 0x00, 0x00, 0x00, 0x00, 0x00,
0x00, 0x00, 0x0E, 0x00, 0x00, 0x00, 0x70, 0x00, 0x00, 0x00, 0x00, 0x00, 0x00, 0x00, 0x00, 0x00,
0x00, 0x01, 0xFE, 0x00, 0x00, 0x00, 0x00, 0x00, 0x00, 0x00, 0x00, 0x00, 0x00, 0x00, 0x00, 0x00,
0xFF, 0xFF, 0xF0, 0x00, 0x00, 0x00, 0x00, 0x00, 0x00, 0x00, 0x00, 0x00, 0x00, 0x00, 0x00, 0x00,
0x03, 0xFF, 0x80, 0x00, 0x00, 0x00, 0x00, 0x00, 0x00, 0x00, 0x00, 0x00, 0x00, 0x00, 0x00, 0x00,
0x00, 0x00, 0x00, 0x00, 0x00, 0x00, 0x00, 0x00, 0x00, 0x00, 0x00, 0x00, 0x00, 0x00, 0x00, 0x00,
};
#define ARABIC_الفجر_WIDTH 128
#define ARABIC_الفجر_HEIGHT 24

// الشروق
const uint8_t arabic_الشروق[] = {
0x00, 0x00, 0x00, 0x00, 0x00, 0x00, 0x00, 0x00, 0x00, 0x00, 0x00, 0x00, 0x00, 0x03, 0x00, 0x70,
0x00, 0x00, 0x00, 0x00, 0x00, 0x00, 0x00, 0x00, 0x00, 0x00, 0x00, 0x00, 0x00, 0x0F, 0x00, 0x70,
0x00, 0x00, 0x00, 0x18, 0x00, 0x00, 0x00, 0x00, 0x00, 0x00, 0x00, 0x00, 0x00, 0x03, 0x01, 0xF0,
0x00, 0x00, 0x0F, 0xFE, 0x00, 0x00, 0x00, 0x00, 0x00, 0x00, 0x00, 0x00, 0x00, 0x03, 0x01, 0xF0,
0x00, 0x00, 0x3F, 0xFE, 0x00, 0x00, 0x00, 0x00, 0x00, 0x00, 0x00, 0x30, 0x00, 0x03, 0x00, 0x70,
0x00, 0x00, 0x03, 0x80, 0x00, 0x00, 0x00, 0x00, 0x00, 0x00, 0x00, 0xFC, 0x00, 0x03, 0x00, 0x70,
0x00, 0x00, 0x00, 0x00, 0x00, 0x00, 0x00, 0x00, 0x00, 0x00, 0x00, 0x3C, 0x00, 0x03, 0x00, 0x70,
0x00, 0x00, 0x00, 0x00, 0x00, 0x00, 0x00, 0x00, 0x00, 0x00, 0x00, 0xFF, 0xE0, 0x03, 0x00, 0x70,
0x00, 0x00, 0x00, 0x78, 0x00, 0x00, 0x00, 0x00, 0x00, 0x00, 0x07, 0xFF, 0x80, 0x03, 0x00, 0x7C,
0x00, 0x00, 0x03, 0xFE, 0x00, 0x00, 0x00, 0x00, 0x00, 0x00, 0x00, 0xF0, 0x00, 0x03, 0xE0, 0x7C,
0x00, 0x60, 0x03, 0x9E, 0x00, 0x01, 0xF0, 0x00, 0x00, 0x00, 0x00, 0x00, 0x00, 0x00, 0xE0, 0x7C,
0x01, 0x80, 0x0F, 0xFF, 0xC0, 0x07, 0xFC, 0x00, 0x00, 0x00, 0x00, 0x00, 0x00, 0x00, 0xE0, 0x7C,
0x0E, 0x00, 0x03, 0xF9, 0xC0, 0x07, 0xFC, 0x00, 0x00, 0xC0, 0x18, 0x0C, 0x1E, 0x00, 0xE0, 0x0C,
0x0E, 0x00, 0x00, 0x01, 0xC0, 0x07, 0xFC, 0x00, 0x00, 0xC0, 0x7F, 0xFC, 0x1F, 0xC3, 0x00, 0x0C,
0x0E, 0x00, 0x00, 0x01, 0xC0, 0x07, 0xFC, 0x00, 0x03, 0xFF, 0xFF, 0xFF, 0xE7, 0xFF, 0x00, 0x0C,
0x3E, 0x00, 0x00, 0x06, 0x00, 0x00, 0x0C, 0x00, 0x00, 0xFF, 0xFF, 0xCF, 0xE1, 0xFC, 0x00, 0x0C,
0x0F, 0x80, 0x00, 0x7E, 0x00, 0x00, 0x70, 0x00, 0x00, 0xC0, 0x00, 0x00, 0x00, 0x00, 0x00, 0x00,
0x0F, 0xFF, 0xFF, 0xF8, 0x00, 0x01, 0xF0, 0x00, 0x00, 0xC0, 0x00, 0x00, 0x00, 0x00, 0x00, 0x00,
0x01, 0xFF, 0xFF, 0xE0, 0x00, 0x07, 0x80, 0x00, 0x00, 0xC0, 0x00, 0x00, 0x00, 0x00, 0x00, 0x00,
0x00, 0x7F, 0xFC, 0x00, 0x00, 0x1F, 0x80, 0x00, 0x03, 0x00, 0x00, 0x00, 0x00, 0x00, 0x00, 0x00,
0x00, 0x00, 0x00, 0x01, 0xFF, 0xF8, 0x00, 0x00, 0x7F, 0x00, 0x00, 0x00, 0x00, 0x00, 0x00, 0x00,
0x00, 0x00, 0x00, 0x00, 0x00, 0x00, 0x03, 0xFF, 0xFC, 0x00, 0x00, 0x00, 0x00, 0x00, 0x00, 0x00,
0x00, 0x00, 0x00, 0x00, 0x00, 0x00, 0x00, 0x3F, 0xE0, 0x00, 0x00, 0x00, 0x00, 0x00, 0x00, 0x00,
0x00, 0x00, 0x00, 0x00, 0x00, 0x00, 0x00, 0x00, 0x00, 0x00, 0x00, 0x00, 0x00, 0x00, 0x00, 0x00,
};
#define ARABIC_الشروق_WIDTH 128
#define ARABIC_الشروق_HEIGHT 24

// الظهر
const uint8_t arabic_الظهر[] = {
0x00, 0x00, 0x00, 0x00, 0x00, 0x00, 0x00, 0x00, 0xE0, 0x00, 0x00, 0x00, 0x00, 0x00, 0x00, 0x00,
0x00, 0x00, 0x00, 0x00, 0x00, 0x00, 0x00, 0x00, 0xE0, 0x00, 0x00, 0x00, 0x07, 0x00, 0x0E, 0x00,
0x00, 0x00, 0x00, 0x00, 0x00, 0x00, 0x00, 0x07, 0xFC, 0x00, 0x00, 0x00, 0x3F, 0x00, 0x0E, 0x00,
0x00, 0x00, 0x00, 0x00, 0x00, 0x00, 0x00, 0x00, 0xE0, 0x00, 0x00, 0x00, 0x07, 0x00, 0x7E, 0x00,
0x00, 0x00, 0x00, 0x00, 0x00, 0x00, 0x00, 0x00, 0xE0, 0x00, 0x00, 0x00, 0x07, 0x00, 0x7E, 0x00,
0x00, 0x00, 0x00, 0x00, 0x00, 0x00, 0x00, 0x00, 0xE0, 0x01, 0xF8, 0x00, 0x07, 0x00, 0x0E, 0x00,
0x00, 0x00, 0x00, 0x00, 0x00, 0x00, 0x00, 0x00, 0xE0, 0x01, 0xFF, 0x00, 0x07, 0x00, 0x0E, 0x00,
0x00, 0x00, 0x00, 0x00, 0x00, 0x00, 0x00, 0x00, 0xE0, 0x00, 0x38, 0x00, 0x07, 0x00, 0x0E, 0x00,
0x00, 0x00, 0x00, 0x00, 0x00, 0x00, 0x00, 0x00, 0xE0, 0x00, 0x00, 0x00, 0x07, 0x00, 0x0E, 0x00,
0x00, 0x00, 0x00, 0x00, 0x00, 0x00, 0x00, 0x00, 0xE0, 0x00, 0x00, 0x00, 0x07, 0x00, 0x0F, 0xC0,
0x00, 0x00, 0x00, 0x00, 0x00, 0x00, 0x70, 0x00, 0xE0, 0x00, 0x3F, 0x00, 0x07, 0xE0, 0x0F, 0xC0,
0x00, 0x00, 0x00, 0x00, 0x00, 0x03, 0xF0, 0x00, 0xE0, 0x0F, 0xFF, 0xE0, 0x00, 0xE0, 0x0F, 0xC0,
0x00, 0x00, 0x00, 0x00, 0x00, 0xE0, 0x70, 0x00, 0xFF, 0x80, 0x07, 0xE0, 0x00, 0xE0, 0x01, 0xC0,
0x00, 0x00, 0x00, 0xE0, 0x00, 0xE3, 0xF0, 0x00, 0xFC, 0x00, 0x3F, 0xE0, 0x00, 0xE0, 0x01, 0xC0,
0x00, 0x00, 0x00, 0xE0, 0x07, 0xFF, 0x80, 0x07, 0xE0, 0x7F, 0xFF, 0x00, 0x07, 0x00, 0x01, 0xC0,
0x00, 0x00, 0x07, 0xFF, 0xFF, 0xFF, 0xFF, 0xFF, 0xFF, 0xFF, 0xFF, 0xFF, 0xFF, 0x00, 0x01, 0xC0,
0x00, 0x00, 0x00, 0xFF, 0xFF, 0xFF, 0xFF, 0xFF, 0xFF, 0xFF, 0xFF, 0xFF, 0xF8, 0x00, 0x01, 0xC0,
0x00, 0x00, 0x00, 0xE0, 0x07, 0xFF, 0xF0, 0x00, 0x00, 0x00, 0x00, 0x00, 0x00, 0x00, 0x00, 0x00,
0x00, 0x00, 0x00, 0xE0, 0x00, 0xE0, 0x7E, 0x00, 0x00, 0x00, 0x00, 0x00, 0x00, 0x00, 0x00, 0x00,
0x00, 0x00, 0x00, 0xE0, 0x00, 0xE0, 0x0E, 0x00, 0x00, 0x00, 0x00, 0x00, 0x00, 0x00, 0x00, 0x00,
0x00, 0x00, 0x07, 0x00, 0x00, 0xFF, 0xFE, 0x00, 0x00, 0x00, 0x00, 0x00, 0x00, 0x00, 0x00, 0x00,
0x00, 0x01, 0xFF, 0x00, 0x00, 0x1F, 0xF0, 0x00, 0x00, 0x00, 0x00, 0x00, 0x00, 0x00, 0x00, 0x00,
0xFF, 0xFF, 0xF8, 0x00, 0x00, 0x03, 0x80, 0x00, 0x00, 0x00, 0x00, 0x00, 0x00, 0x00, 0x00, 0x00,
0x03, 0xFF, 0xC0, 0x00, 0x00, 0x00, 0x00, 0x00, 0x00, 0x00, 0x00, 0x00, 0x00, 0x00, 0x00, 0x00,
};
#define ARABIC_الظهر_WIDTH 128
#define ARABIC_الظهر_HEIGHT 24

// العصر
const uint8_t arabic_العصر[] = {
0x00, 0x00, 0x00, 0x00, 0x00, 0x00, 0x00, 0x00, 0x00, 0x00, 0x00, 0x00, 0x01, 0xC0, 0x07, 0x00,
0x00, 0x00, 0x00, 0x00, 0x00, 0x00, 0x00, 0x00, 0x00, 0x00, 0x00, 0x00, 0x0F, 0xC0, 0x07, 0x00,
0x00, 0x00, 0x00, 0x00, 0x00, 0x00, 0x00, 0x00, 0x00, 0x00, 0x00, 0x00, 0x01, 0xC0, 0x3F, 0x00,
0x00, 0x00, 0x00, 0x00, 0x00, 0x00, 0x00, 0x00, 0x00, 0x00, 0x00, 0x00, 0x01, 0xC0, 0x3F, 0x00,
0x00, 0x00, 0x00, 0x00, 0x00, 0x00, 0x00, 0x00, 0x00, 0x00, 0x00, 0x00, 0x01, 0xC0, 0x07, 0x00,
0x00, 0x00, 0x00, 0x00, 0x00, 0x00, 0x00, 0x00, 0x00, 0x00, 0x00, 0x00, 0x01, 0xC0, 0x07, 0x00,
0x00, 0x00, 0x00, 0x00, 0x00, 0x00, 0x00, 0x00, 0x00, 0x00, 0x00, 0x00, 0x01, 0xC0, 0x07, 0x00,
0x00, 0x00, 0x00, 0x00, 0x00, 0x00, 0x00, 0x00, 0x00, 0x00, 0x00, 0x00, 0x01, 0xC0, 0x07, 0x00,
0x00, 0x00, 0x00, 0x00, 0x00, 0x00, 0x00, 0x00, 0x00, 0x00, 0x00, 0x00, 0x01, 0xC0, 0x07, 0xC0,
0x00, 0x00, 0x00, 0x00, 0x00, 0x00, 0x00, 0x07, 0xFC, 0x00, 0x00, 0x00, 0x01, 0xF8, 0x07, 0xC0,
0x00, 0x00, 0x00, 0x00, 0x00, 0x00, 0x00, 0xFF, 0xFF, 0x00, 0x7F, 0xF0, 0x00, 0x38, 0x07, 0xC0,
0x00, 0x00, 0x00, 0x00, 0x00, 0x00, 0x07, 0xFF, 0xFF, 0x03, 0xFF, 0xFE, 0x00, 0x38, 0x07, 0xC0,
0x00, 0x00, 0x03, 0x80, 0x70, 0x01, 0xC0, 0x00, 0xFC, 0x00, 0x7F, 0xFE, 0x00, 0x38, 0x00, 0xC0,
0x00, 0x00, 0x03, 0x81, 0xFF, 0xC6, 0x00, 0xFF, 0xFF, 0x00, 0x7F, 0xFE, 0x01, 0xC0, 0x00, 0xC0,
0x00, 0x00, 0x1F, 0xFF, 0x8F, 0xFF, 0xFF, 0xFF, 0xFF, 0xFF, 0xE0, 0x7F, 0xFF, 0xC0, 0x00, 0xC0,
0x00, 0x00, 0x03, 0xFE, 0x00, 0x3F, 0xFF, 0xC0, 0x1F, 0xFF, 0x80, 0x01, 0xFE, 0x00, 0x00, 0xC0,
0x00, 0x00, 0x03, 0x80, 0x01, 0xC0, 0x00, 0x00, 0x00, 0x00, 0x00, 0x00, 0x00, 0x00, 0x00, 0x00,
0x00, 0x00, 0x03, 0x80, 0x01, 0xC0, 0x00, 0x00, 0x00, 0x00, 0x00, 0x00, 0x00, 0x00, 0x00, 0x00,
0x00, 0x00, 0x03, 0x80, 0x00, 0x00, 0x00, 0x00, 0x00, 0x00, 0x00, 0x00, 0x00, 0x00, 0x00, 0x00,
0x00, 0x00, 0x1C, 0x00, 0x00, 0x00, 0x00, 0x00, 0x00, 0x00, 0x00, 0x00, 0x00, 0x00, 0x00, 0x00,
0x00, 0x03, 0xFC, 0x00, 0x00, 0x00, 0x00, 0x00, 0x00, 0x00, 0x00, 0x00, 0x00, 0x00, 0x00, 0x00,
0xFF, 0xFF, 0xE0, 0x00, 0x00, 0x00, 0x00, 0x00, 0x00, 0x00, 0x00, 0x00, 0x00, 0x00, 0x00, 0x00,
0x03, 0xFF, 0x80, 0x00, 0x00, 0x00, 0x00, 0x00, 0x00, 0x00, 0x00, 0x00, 0x00, 0x00, 0x00, 0x00,
0x00, 0x00, 0x00, 0x00, 0x00, 0x00, 0x00, 0x00, 0x00, 0x00, 0x00, 0x00, 0x00, 0x00, 0x00, 0x00,
};
#define ARABIC_العصر_WIDTH 128
#define ARABIC_العصر_HEIGHT 24

// المغرب
const uint8_t arabic_المغرب[] = {
0x00, 0x00, 0x00, 0x00, 0x00, 0x00, 0x00, 0x00, 0x00, 0x00, 0x00, 0x00, 0x00, 0x01, 0x80, 0x70,
0x00, 0x00, 0x00, 0x00, 0x00, 0x00, 0x00, 0x00, 0x00, 0x00, 0x00, 0x00, 0x00, 0x0F, 0x80, 0x70,
0x00, 0x00, 0x00, 0x00, 0x00, 0x00, 0x00, 0x00, 0x00, 0x00, 0x00, 0x00, 0x00, 0x01, 0x81, 0xF0,
0x00, 0x00, 0x00, 0x00, 0x00, 0x00, 0x00, 0x00, 0x00, 0x00, 0x00, 0x00, 0x00, 0x01, 0x81, 0xF0,
0x00, 0x00, 0x00, 0x00, 0x00, 0x00, 0x00, 0x00, 0x07, 0xC0, 0x00, 0x00, 0x00, 0x01, 0x80, 0x70,
0x00, 0x00, 0x00, 0x00, 0x00, 0x00, 0x00, 0x00, 0x1F, 0xF0, 0x00, 0x00, 0x00, 0x01, 0x80, 0x70,
0x00, 0x00, 0x00, 0x00, 0x00, 0x00, 0x00, 0x00, 0x00, 0xC0, 0x00, 0x00, 0x00, 0x01, 0x80, 0x70,
0x00, 0x00, 0x00, 0x00, 0x00, 0x00, 0x00, 0x00, 0x00, 0x00, 0x00, 0x00, 0x00, 0x01, 0x80, 0x70,
0x00, 0x00, 0x00, 0x00, 0x00, 0x60, 0x00, 0x00, 0x00, 0x00, 0x00, 0x00, 0x00, 0x01, 0x80, 0x7C,
0x01, 0x80, 0x00, 0x00, 0x00, 0x60, 0x00, 0x00, 0x00, 0x00, 0x00, 0x00, 0x00, 0x01, 0xE0, 0x7C,
0x0E, 0x00, 0x00, 0x00, 0x00, 0x7C, 0x00, 0x00, 0x07, 0xFC, 0x00, 0x00, 0x00, 0x00, 0x60, 0x7C,
0x0E, 0x00, 0x00, 0x00, 0x00, 0x1C, 0x00, 0x00, 0x1F, 0xFF, 0x00, 0x07, 0xC0, 0x00, 0x60, 0x7C,
0x0F, 0x80, 0x00, 0x00, 0x01, 0xE0, 0x00, 0x06, 0x07, 0xFF, 0x00, 0x18, 0x3C, 0x00, 0x60, 0x0C,
0x0F, 0xF8, 0x00, 0x0F, 0xFF, 0xE0, 0x00, 0x06, 0x07, 0xFF, 0x00, 0x7F, 0xFF, 0xC1, 0x80, 0x0C,
0x01, 0xFF, 0xFF, 0xFF, 0xFE, 0x00, 0x00, 0x1F, 0xFF, 0x0F, 0xFF, 0x9F, 0xFF, 0xFF, 0x80, 0x0C,
0x00, 0x7F, 0xFF, 0xFF, 0x80, 0x00, 0x00, 0x07, 0xF8, 0x00, 0xFE, 0x07, 0xFC, 0xFE, 0x00, 0x0C,
0x00, 0x00, 0x00, 0x00, 0x00, 0x00, 0x00, 0x06, 0x00, 0x00, 0x00, 0x00, 0x0C, 0x00, 0x00, 0x00,
0x00, 0x00, 0x00, 0x00, 0x00, 0x00, 0x00, 0x06, 0x00, 0x00, 0x00, 0x00, 0x00, 0x00, 0x00, 0x00,
0x00, 0x00, 0x00, 0x00, 0x00, 0x00, 0x00, 0x06, 0x00, 0x00, 0x00, 0x00, 0x00, 0x00, 0x00, 0x00,
0x00, 0x00, 0x00, 0xF0, 0x00, 0x00, 0x00, 0x18, 0x00, 0x00, 0x00, 0x00, 0x00, 0x00, 0x00, 0x00,
0x00, 0x00, 0x03, 0xF0, 0x00, 0x00, 0x03, 0xF8, 0x00, 0x00, 0x00, 0x00, 0x00, 0x00, 0x00, 0x00,
0x00, 0x00, 0x00, 0xC0, 0x00, 0x1F, 0xFF, 0xE0, 0x00, 0x00, 0x00, 0x00, 0x00, 0x00, 0x00, 0x00,
0x00, 0x00, 0x00, 0x00, 0x00, 0x00, 0xFF, 0x00, 0x00, 0x00, 0x00, 0x00, 0x00, 0x00, 0x00, 0x00,
0x00, 0x00, 0x00, 0x00, 0x00, 0x00, 0x00, 0x00, 0x00, 0x00, 0x00, 0x00, 0x00, 0x00, 0x00, 0x00,
};
#define ARABIC_المغرب_WIDTH 128
#define ARABIC_المغرب_HEIGHT 24

// العشاء
const uint8_t arabic_العشاء[] = {
0x00, 0x00, 0x00, 0x1C, 0x00, 0x00, 0x00, 0x00, 0x00, 0x00, 0x00, 0x00, 0x00, 0x38, 0x00, 0xE0,
0x00, 0x00, 0x00, 0x1C, 0x00, 0x00, 0x00, 0x00, 0x00, 0x00, 0x00, 0x00, 0x01, 0xF8, 0x00, 0xE0,
0x00, 0x00, 0x00, 0x1C, 0x00, 0x00, 0x00, 0x00, 0x00, 0x00, 0x00, 0x00, 0x01, 0xF8, 0x00, 0xE0,
0x00, 0x00, 0x00, 0x1C, 0x00, 0x00, 0x00, 0x00, 0x00, 0x00, 0x00, 0x00, 0x00, 0x38, 0x07, 0xE0,
0x00, 0x00, 0x00, 0x1F, 0x80, 0x00, 0x00, 0x00, 0x00, 0x00, 0x00, 0x00, 0x00, 0x38, 0x07, 0xE0,
0x00, 0x00, 0x00, 0x1F, 0x80, 0x00, 0x00, 0x70, 0x00, 0x00, 0x00, 0x00, 0x00, 0x38, 0x00, 0xE0,
0x00, 0x00, 0x00, 0x03, 0x80, 0x00, 0x03, 0xFE, 0x00, 0x00, 0x00, 0x00, 0x00, 0x38, 0x00, 0xE0,
0x00, 0x00, 0x00, 0x03, 0x80, 0x00, 0x03, 0xFE, 0x00, 0x00, 0x00, 0x00, 0x00, 0x38, 0x00, 0xE0,
0x00, 0x00, 0x00, 0x03, 0x80, 0x00, 0x00, 0x7E, 0x00, 0x00, 0x00, 0x00, 0x00, 0x38, 0x00, 0xE0,
0x00, 0x00, 0x00, 0x03, 0x80, 0x00, 0x03, 0xFF, 0xF0, 0x00, 0x00, 0x00, 0x00, 0x38, 0x00, 0xE0,
0x00, 0x00, 0x00, 0x03, 0x80, 0x00, 0x0F, 0xFF, 0x80, 0x00, 0x00, 0x00, 0x00, 0x38, 0x00, 0xF8,
0x00, 0x00, 0x00, 0x03, 0x80, 0x00, 0x03, 0xF0, 0x00, 0x00, 0x00, 0x00, 0x00, 0x3F, 0x00, 0xF8,
0x00, 0x00, 0x00, 0x03, 0x80, 0x00, 0x03, 0xF0, 0x00, 0x00, 0x00, 0x00, 0x00, 0x3F, 0x00, 0xF8,
0x00, 0xFF, 0x00, 0x03, 0x80, 0x00, 0x00, 0x00, 0x00, 0x00, 0x0F, 0xFE, 0x00, 0x07, 0x00, 0xF8,
0x07, 0xFC, 0x00, 0x03, 0x80, 0x00, 0x00, 0x00, 0x00, 0x00, 0x3F, 0xFF, 0xC0, 0x07, 0x00, 0xF8,
0x07, 0x00, 0x00, 0x03, 0x80, 0x00, 0x00, 0x0E, 0x01, 0xC0, 0x3F, 0xFF, 0xF8, 0x07, 0x00, 0x18,
0x1F, 0xFF, 0xFC, 0x03, 0x80, 0x00, 0x70, 0x0E, 0x0F, 0xC0, 0x0F, 0xFF, 0xC0, 0x07, 0x00, 0x18,
0x1F, 0xFF, 0xFC, 0x03, 0x80, 0x00, 0x70, 0x0E, 0x0F, 0xC0, 0x0F, 0xFF, 0xC0, 0x07, 0x00, 0x18,
0x07, 0xFF, 0xE0, 0x03, 0xE0, 0x03, 0xFF, 0xFE, 0x0F, 0xF0, 0x0F, 0xFF, 0xC0, 0x38, 0x00, 0x18,
0x00, 0xFC, 0x00, 0x03, 0xFF, 0xFF, 0xFF, 0xFF, 0xF1, 0xFF, 0xFE, 0x07, 0xFF, 0xF8, 0x00, 0x18,
0x07, 0x00, 0x00, 0x00, 0x7F, 0xFF, 0xFF, 0x8F, 0xF0, 0x3F, 0xF0, 0x00, 0x3F, 0xC0, 0x00, 0x18,
0x00, 0x00, 0x00, 0x00, 0x00, 0x00, 0x00, 0x00, 0x00, 0x00, 0x00, 0x00, 0x00, 0x00, 0x00, 0x00,
0x00, 0x00, 0x00, 0x00, 0x00, 0x00, 0x00, 0x00, 0x00, 0x00, 0x00, 0x00, 0x00, 0x00, 0x00, 0x00,
0x00, 0x00, 0x00, 0x00, 0x00, 0x00, 0x00, 0x00, 0x00, 0x00, 0x00, 0x00, 0x00, 0x00, 0x00, 0x00,
};
#define ARABIC_العشاء_WIDTH 128
#define ARABIC_العشاء_HEIGHT 24
```

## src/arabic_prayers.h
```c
#ifndef ARABIC_PRAYERS_H
#define ARABIC_PRAYERS_H

#include <stdint.h>

// مواقيت الصلاة (Prayer Times)
extern const uint8_t arabic_مواقيت_الصلاة[];
#define ARABIC_مواقيت_الصلاة_WIDTH 128
#define ARABIC_مواقيت_الصلاة_HEIGHT 24

// الفجر (Fajr)
extern const uint8_t arabic_الفجر[];
#define ARABIC_الفجر_WIDTH 128
#define ARABIC_الفجر_HEIGHT 24

// الشروق (Sunrise)
extern const uint8_t arabic_الشروق[];
#define ARABIC_الشروق_WIDTH 128
#define ARABIC_الشروق_HEIGHT 24

// الظهر (Dhuhr)
extern const uint8_t arabic_الظهر[];
#define ARABIC_الظهر_WIDTH 128
#define ARABIC_الظهر_HEIGHT 24

// العصر (Asr)
extern const uint8_t arabic_العصر[];
#define ARABIC_العصر_WIDTH 128
#define ARABIC_العصر_HEIGHT 24

// المغرب (Maghrib)
extern const uint8_t arabic_المغرب[];
#define ARABIC_المغرب_WIDTH 128
#define ARABIC_المغرب_HEIGHT 24

// العشاء (Isha)
extern const uint8_t arabic_العشاء[];
#define ARABIC_العشاء_WIDTH 128
#define ARABIC_العشاء_HEIGHT 24

#endif // ARABIC_PRAYERS_H
```

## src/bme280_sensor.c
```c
#include "bme280_sensor.h"
#include <zephyr/device.h>
#include <zephyr/drivers/sensor.h>
#include <zephyr/logging/log.h>

LOG_MODULE_REGISTER(bme280_sensor, LOG_LEVEL_INF);

static const struct device *bme280_dev = NULL;
static bme280_data_t last_reading = {0};

int bme280_sensor_init(void)
{
    // Get BME280 device from devicetree
    bme280_dev = DEVICE_DT_GET_ANY(bosch_bme280);

    if (bme280_dev == NULL) {
        LOG_ERR("BME280 device not found in devicetree");
        return -ENODEV;
    }

    if (!device_is_ready(bme280_dev)) {
        LOG_ERR("BME280 device not ready");
        bme280_dev = NULL;
        return -ENODEV;
    }

    LOG_INF("BME280 sensor initialized successfully");

    // Initialize last_reading
    last_reading.valid = false;
    last_reading.temperature = 0.0f;
    last_reading.humidity = 0.0f;
    last_reading.pressure = 0.0f;

    return 0;
}

int bme280_sensor_read(bme280_data_t *data)
{
    if (data == NULL) {
        return -EINVAL;
    }

    if (bme280_dev == NULL || !device_is_ready(bme280_dev)) {
        LOG_ERR("BME280 device not ready for reading");
        data->valid = false;
        return -ENODEV;
    }

    // Fetch sensor data
    int ret = sensor_sample_fetch(bme280_dev);
    if (ret) {
        LOG_ERR("Failed to fetch sensor data: %d", ret);
        data->valid = false;
        return ret;
    }

    // Read temperature
    struct sensor_value temp_val;
    ret = sensor_channel_get(bme280_dev, SENSOR_CHAN_AMBIENT_TEMP, &temp_val);
    if (ret) {
        LOG_ERR("Failed to get temperature: %d", ret);
        data->valid = false;
        return ret;
    }

    // Read humidity
    struct sensor_value humid_val;
    ret = sensor_channel_get(bme280_dev, SENSOR_CHAN_HUMIDITY, &humid_val);
    if (ret) {
        LOG_ERR("Failed to get humidity: %d", ret);
        data->valid = false;
        return ret;
    }

    // Read pressure
    struct sensor_value press_val;
    ret = sensor_channel_get(bme280_dev, SENSOR_CHAN_PRESS, &press_val);
    if (ret) {
        LOG_ERR("Failed to get pressure: %d", ret);
        data->valid = false;
        return ret;
    }

    // Convert sensor values to floats
    data->temperature = sensor_value_to_double(&temp_val);
    data->humidity = sensor_value_to_double(&humid_val);
    data->pressure = sensor_value_to_double(&press_val) / 1000.0; // Convert Pa to hPa
    data->valid = true;

    // Update last reading
    last_reading = *data;

    LOG_DBG("BME280: Temp=%.1f°C, Humid=%.1f%%, Press=%.1fhPa",
            (double)data->temperature, (double)data->humidity, (double)data->pressure);

    return 0;
}

int bme280_sensor_get_data(bme280_data_t *data)
{
    if (data == NULL) {
        return -EINVAL;
    }

    if (!last_reading.valid) {
        LOG_WRN("No valid sensor data available yet");
        return -ENODATA;
    }

    *data = last_reading;
    return 0;
}

bool bme280_sensor_is_ready(void)
{
    return (bme280_dev != NULL && device_is_ready(bme280_dev));
}
```

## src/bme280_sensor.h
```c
#ifndef BME280_SENSOR_H
#define BME280_SENSOR_H

#include <zephyr/kernel.h>
#include <stdbool.h>

/**
 * @brief BME280 sensor data structure
 */
typedef struct {
    float temperature;  // Temperature in Celsius
    float humidity;     // Relative humidity in %
    float pressure;     // Pressure in hPa
    bool valid;         // Data validity flag
} bme280_data_t;

/**
 * @brief Initialize BME280 sensor
 * @return 0 on success, negative error code on failure
 */
int bme280_sensor_init(void);

/**
 * @brief Read all sensor data from BME280
 * @param data Pointer to structure to store sensor readings
 * @return 0 on success, negative error code on failure
 */
int bme280_sensor_read(bme280_data_t *data);

/**
 * @brief Get last valid sensor reading
 * @param data Pointer to structure to store sensor readings
 * @return 0 on success, negative error code if no valid data
 */
int bme280_sensor_get_data(bme280_data_t *data);

/**
 * @brief Check if BME280 sensor is available
 * @return true if sensor is ready, false otherwise
 */
bool bme280_sensor_is_ready(void);

#endif // BME280_SENSOR_H
```
